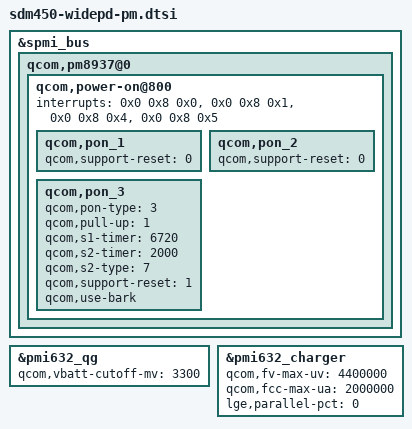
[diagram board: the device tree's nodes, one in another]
/*
 * Copyright (c) 2018, The Linux Foundation. All rights reserved.
 *
 * This program is free software; you can redistribute it and/or modify
 * it under the terms of the GNU General Public License version 2 and
 * only version 2 as published by the Free Software Foundation.
 *
 * This program is distributed in the hope that it will be useful,
 * but WITHOUT ANY WARRANTY; without even the implied warranty of
 * MERCHANTABILITY or FITNESS FOR A PARTICULAR PURPOSE.  See the
 * GNU General Public License for more details.
 */

#include "../sdm450-widepd_common/sdm450-widepd_common-pm.dtsi"


&spmi_bus {
	qcom,pm8937@0 {
		qcom,power-on@800 {
			interrupts = <0x0 0x8 0x0>,
				     <0x0 0x8 0x1>,
				     <0x0 0x8 0x4>,
				     <0x0 0x8 0x5>;
			interrupt-names = "kpdpwr", "resin",
				"resin-bark", "kpdpwr-resin-bark";

			qcom,pon_1 {
				status = "ok";
				qcom,support-reset = <0>;
			};
			qcom,pon_2 {
				status = "ok";
				qcom,support-reset = <0>;
			};
			qcom,pon_3 {
				status = "ok";
				qcom,pon-type = <3>;
				qcom,pull-up = <1>;
				qcom,s1-timer = <6720>;
				qcom,s2-timer = <2000>;
				qcom,s2-type = <7>;
				qcom,support-reset = <1>;
				qcom,use-bark;
			};
		};
	};
};

&pmi632_qg {
    qcom,vbatt-cutoff-mv = <3300>;
};

&pmi632_charger {
    qcom,fv-max-uv = <4400000>;
    qcom,fcc-max-ua = <2000000>;
    lge,parallel-pct = <0>;
};
/*
&pmi632_pwm {
    qcom,lut-patterns = <0>;

	lpg@1 {
        qcom,ramp-high-index = <47>;
    };

	lpg@2 {
        qcom,ramp-high-index = <47>;
    };

	lpg@3 {
        qcom,ramp-high-index = <47>;
    };
};*/
